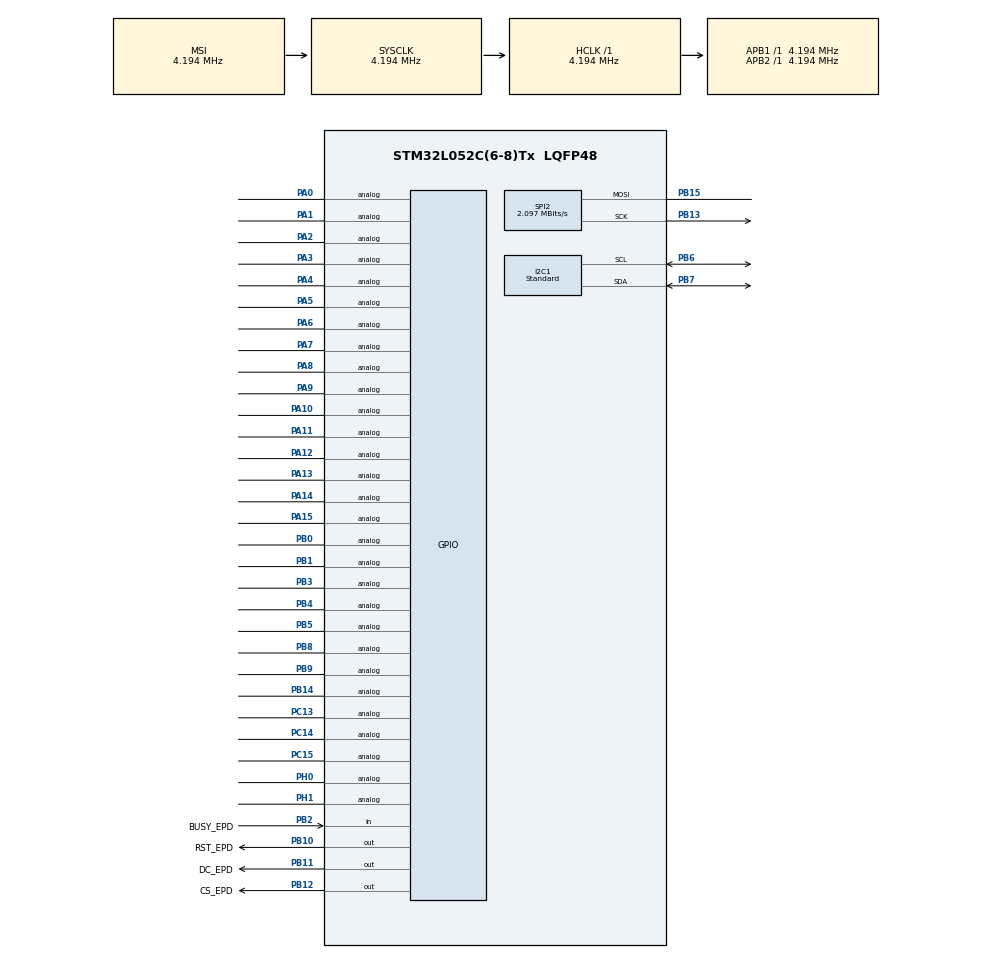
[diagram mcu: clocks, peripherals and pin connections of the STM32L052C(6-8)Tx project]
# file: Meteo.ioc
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ADC.SamplingTime=ADC_SAMPLETIME_160CYCLES_5
I2C1.Analog_Filter=I2C_ANALOGFILTER_DISABLE
I2C1.I2C_Speed_Mode=I2C_Standard
I2C1.Timing=0x00100E16
Mcu.Family=STM32L0
Mcu.Name=STM32L052C(6-8)Tx
Mcu.Package=LQFP48
NVIC.RTC_IRQn=true\:0\:0\:false\:false\:true\:true\:true
PA0.Signal=GPIO_Analog
PA1.Signal=GPIO_Analog
PA10.Signal=GPIO_Analog
PA11.Signal=GPIO_Analog
PA12.Signal=GPIO_Analog
PA13.Signal=GPIO_Analog
PA14.Signal=GPIO_Analog
PA15.Signal=GPIO_Analog
PA2.Signal=GPIO_Analog
PA3.Signal=GPIO_Analog
PA4.Signal=GPIO_Analog
PA5.Signal=GPIO_Analog
PA6.Signal=GPIO_Analog
PA7.Signal=GPIO_Analog
PA8.Signal=GPIO_Analog
PA9.Signal=GPIO_Analog
PB0.Signal=GPIO_Analog
PB1.Signal=GPIO_Analog
PB10.GPIO_Label=RST_EPD
PB10.GPIO_PuPd=GPIO_PULLUP
PB10.GPIO_Speed=GPIO_SPEED_FREQ_LOW
PB10.PinState=GPIO_PIN_SET
PB10.Signal=GPIO_Output
PB11.GPIO_Label=DC_EPD
PB11.GPIO_Speed=GPIO_SPEED_FREQ_LOW
PB11.Signal=GPIO_Output
PB12.GPIO_Label=CS_EPD
PB12.PinState=GPIO_PIN_SET
PB12.Signal=GPIO_Output
PB13.Mode=Simplex_Bidirectional_Master
PB13.Signal=SPI2_SCK
PB14.Signal=GPIO_Analog
PB15.GPIO_Speed=GPIO_SPEED_FREQ_VERY_HIGH
PB15.Mode=Simplex_Bidirectional_Master
PB15.Signal=SPI2_MOSI
PB2.GPIO_Label=BUSY_EPD
PB2.Signal=GPIO_Input
PB3.Signal=GPIO_Analog
PB4.Signal=GPIO_Analog
PB5.Signal=GPIO_Analog
PB6.Mode=I2C
PB6.Signal=I2C1_SCL
PB7.Mode=I2C
PB7.Signal=I2C1_SDA
PB8.Signal=GPIO_Analog
PB9.Signal=GPIO_Analog
PC13.Signal=GPIO_Analog
PC14-OSC32_IN.Signal=GPIO_Analog
PC15-OSC32_OUT.Signal=GPIO_Analog
PH0-OSC_IN.Signal=GPIO_Analog
PH1-OSC_OUT.Signal=GPIO_Analog
ProjectManager.HeapSize=0x200
ProjectManager.StackSize=0x400
ProjectManager.TargetToolchain=MDK-ARM V5
RCC.ADCFreq_Value=16000000
RCC.AHBFreq_Value=4194000
RCC.APB1Freq_Value=4194000
RCC.APB1TimFreq_Value=4194000
RCC.APB2Freq_Value=4194000
RCC.APB2TimFreq_Value=4194000
RCC.HCLKFreq_Value=4194000
RCC.HSE_VALUE=8000000
RCC.HSI16_VALUE=16000000
RCC.HSI48_VALUE=48000000
RCC.HSI_VALUE=16000000
RCC.LSE_VALUE=32768
RCC.MSIClockRange=RCC_MSIRANGE_6
RCC.MSI_VALUE=4194000
RCC.PLLDIV=RCC_PLLDIV_4
RCC.PLLMUL=RCC_PLLMUL_4
RCC.SYSCLKFreq_VALUE=4194000
RCC.Usart2ClockSelection=RCC_USART2CLKSOURCE_SYSCLK
RCC.VCOOutputFreq_Value=64000000
RTC.AsynchPrediv=99
RTC.SynchPrediv=369
RTC.WakeUpClock-WakeUp=RTC_WAKEUPCLOCK_RTCCLK_DIV8
RTC.WakeUpCounter-WakeUp=23124
SPI2.CalculateBaudRate=2.097 MBits/s
SPI2.Direction=SPI_DIRECTION_1LINE
SPI2.Mode=SPI_MODE_MASTER
SPI2.VirtualType=VM_MASTER
SYS.Mode=PWR_PVD_MODE_NORMAL
SYS.PVDLevel=PWR_PVDLEVEL_0
VP_ADC_Vref_Input.Mode=IN-Vrefint
VP_RTC_VS_RTC_Activate.Mode=RTC_Enabled
VP_RTC_VS_RTC_Calendar.Mode=RTC_Calendar
VP_RTC_VS_RTC_WakeUp_intern.Mode=WakeUp
VP_SYS_V_PVD_IN.Mode=Mode_PVD_Int
board=custom

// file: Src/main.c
/* USER CODE BEGIN Header */
/**
  ******************************************************************************
  * @file           : main.c
  * @brief          : Main program body
  ******************************************************************************
  * @attention
  *
  * <h2><center>&copy; Copyright (c) 2021 STMicroelectronics.
  * All rights reserved.</center></h2>
  *
  * This software component is licensed by ST under BSD 3-Clause license,
  * the "License"; You may not use this file except in compliance with the
  * License. You may obtain a copy of the License at:
  *                        opensource.org/licenses/BSD-3-Clause
  *
  ******************************************************************************
  */
/* USER CODE END Header */
#include "main.h"

/* USER CODE BEGIN Includes */
#include "bme280.h"
#include <string.h>
#include <stdint.h>
#include <stdio.h>
#include <stdlib.h>
#include "E-ink_2.13.h"
#include "E-ink_draw.h"

/* USER CODE END Includes */

/* USER CODE BEGIN PTD */
rt_clock RT_C;
float Battery;
/* USER CODE END PTD */

ADC_HandleTypeDef hadc;

I2C_HandleTypeDef hi2c1;

RTC_HandleTypeDef hrtc;

SPI_HandleTypeDef hspi2;

void SystemClock_Config(void);
static void MX_GPIO_Init(void);
static void MX_I2C1_Init(void);
static void MX_SPI2_Init(void);
static void MX_ADC_Init(void);
static void MX_RTC_Init(void);

/* USER CODE BEGIN 0 */
float temperature;
float humidity;
float pressure;
struct bme280_dev dev;
struct bme280_data comp_data;
int8_t rslt;
char Str[12];
uint8_t Old_min=128;
char line1[16];
char line2[16];

//------------------------------------------------------------------------------
// File generated by LCD Assistant
// http://en.radzio.dxp.pl/bitmap_converter/
//------------------------------------------------------------------------------
const unsigned char Batt_Full [] = { // 100% Battery Icon
0x20, 0x00, 0x10, 0x00,
0xFF, 0xFF, 0x03, 0xFB, 0xFB, 0xFB, 0xFB, 0x03, 0xFB, 0xFB, 0xFB, 0xFB, 0x03, 0xFB, 0xFB, 0xFB,
0xFB, 0x03, 0xFB, 0xFB, 0xFB, 0xFB, 0x03, 0xFF, 0xFF, 0xF8, 0xF8, 0x00, 0x00, 0x00, 0x00, 0x00,
0x0F, 0x0F, 0x0C, 0x0D, 0x0D, 0x0D, 0x0D, 0x0C, 0x0D, 0x0D, 0x0D, 0x0D, 0x0C, 0x0D, 0x0D, 0x0D,
0x0D, 0x0C, 0x0D, 0x0D, 0x0D, 0x0D, 0x0C, 0x0F, 0x0F, 0x01, 0x01, 0x00, 0x00, 0x00, 0x00, 0x00
};

const unsigned char Batt_75 [] = { // 75% Battery Icon
0x20, 0x00, 0x10, 0x00,
0xFF, 0xFF, 0x03, 0xFB, 0xFB, 0xFB, 0xFB, 0x03, 0xFB, 0xFB, 0xFB, 0xFB, 0x03, 0xFB, 0xFB, 0xFB,
0xFB, 0x03, 0x03, 0x03, 0x03, 0x03, 0x03, 0xFF, 0xFF, 0xF8, 0xF8, 0x00, 0x00, 0x00, 0x00, 0x00,
0x0F, 0x0F, 0x0C, 0x0D, 0x0D, 0x0D, 0x0D, 0x0C, 0x0D, 0x0D, 0x0D, 0x0D, 0x0C, 0x0D, 0x0D, 0x0D,
0x0D, 0x0C, 0x0C, 0x0C, 0x0C, 0x0C, 0x0C, 0x0F, 0x0F, 0x01, 0x01, 0x00, 0x00, 0x00, 0x00, 0x00};

const unsigned char Batt_50 [] = { // 50% Battery Icon
0x20, 0x00, 0x10, 0x00,
0xFF, 0xFF, 0x03, 0xFB, 0xFB, 0xFB, 0xFB, 0x03, 0xFB, 0xFB, 0xFB, 0xFB, 0x03, 0x03, 0x03, 0x03,
0x03, 0x03, 0x03, 0x03, 0x03, 0x03, 0x03, 0xFF, 0xFF, 0xF8, 0xF8, 0x00, 0x00, 0x00, 0x00, 0x00,
0x0F, 0x0F, 0x0C, 0x0D, 0x0D, 0x0D, 0x0D, 0x0C, 0x0D, 0x0D, 0x0D, 0x0D, 0x0C, 0x0C, 0x0C, 0x0C,
0x0C, 0x0C, 0x0C, 0x0C, 0x0C, 0x0C, 0x0C, 0x0F, 0x0F, 0x01, 0x01, 0x00, 0x00, 0x00, 0x00, 0x00
	};
const unsigned char Batt_25 [] = { // 25% Battery Icon
0x20, 0x00, 0x10, 0x00,
0xFF, 0xFF, 0x03, 0xFB, 0xFB, 0xFB, 0xFB, 0x03, 0x03, 0x03, 0x03, 0x03, 0x03, 0x03, 0x03, 0x03,
0x03, 0x03, 0x03, 0x03, 0x03, 0x03, 0x03, 0xFF, 0xFF, 0xF8, 0xF8, 0x00, 0x00, 0x00, 0x00, 0x00,
0x0F, 0x0F, 0x0C, 0x0D, 0x0D, 0x0D, 0x0D, 0x0C, 0x0C, 0x0C, 0x0C, 0x0C, 0x0C, 0x0C, 0x0C, 0x0C,
0x0C, 0x0C, 0x0C, 0x0C, 0x0C, 0x0C, 0x0C, 0x0F, 0x0F, 0x01, 0x01, 0x00, 0x00, 0x00, 0x00, 0x00
};

const unsigned char Batt_0 [] = { // 0% Battery Icon
0x20, 0x00, 0x10, 0x00,
0xFF, 0xFF, 0x03, 0x03, 0x03, 0x03, 0x03, 0x03, 0x03, 0x03, 0x03, 0x03, 0x03, 0x03, 0x03, 0x03,
0x03, 0x03, 0x03, 0x03, 0x03, 0x03, 0x03, 0xFF, 0xFF, 0xF8, 0xF8, 0x00, 0x00, 0x00, 0x00, 0x00,
0x0F, 0x0F, 0x0C, 0x0C, 0x0C, 0x0C, 0x0C, 0x0C, 0x0C, 0x0C, 0x0C, 0x0C, 0x0C, 0x0C, 0x0C, 0x0C,
0x0C, 0x0C, 0x0C, 0x0C, 0x0C, 0x0C, 0x0C, 0x0F, 0x0F, 0x01, 0x01, 0x00, 0x00, 0x00, 0x00, 0x00};

const unsigned char MainScr [] = { // Main Icon
0xFA, 0x00, 0x80, 0x00,
0x00, 0x00, 0x00, 0x00, 0x00, 0x00, 0x00, 0x00, 0x00, 0x00, 0x00, 0x00, 0x00, 0x00, 0x00, 0x00,
0x00, 0x00, 0x00, 0x00, 0x00, 0x00, 0x00, 0x00, 0x00, 0x00, 0x00, 0x80, 0xE0, 0x60, 0x60, 0x60,
0x60, 0x60, 0x60, 0x60, 0x60, 0xE0, 0xC0, 0x00, 0x00, 0x00, 0x00, 0x00, 0x00, 0x00, 0x00, 0x00,
0x00, 0x00, 0x00, 0x00, 0x00, 0x00, 0x00, 0x00, 0x00, 0x00, 0x00, 0x00, 0x00, 0x00, 0x00, 0x00,
0x00, 0x00, 0x00, 0x00, 0x00, 0x00, 0x00, 0x00, 0x00, 0x00, 0x00, 0x00, 0x00, 0x00, 0x00, 0x00,
0x00, 0x00, 0x00, 0x00, 0x00, 0x00, 0x00, 0x00, 0x00, 0x00, 0x00, 0x00, 0x00, 0x00, 0x00, 0x00,
0x00, 0x00, 0x00, 0x00, 0x00, 0x00, 0x00, 0x00, 0x00, 0x00, 0x00, 0x00, 0x00, 0x00, 0x00, 0x00,
0x00, 0x00, 0x00, 0x00, 0x00, 0x00, 0x00, 0x00, 0x00, 0x00, 0x00, 0x00, 0x00, 0x00, 0x00, 0x00,
0x00, 0x00, 0x00, 0x00, 0x00, 0x00, 0x00, 0x00, 0x00, 0x00, 0x00, 0x00, 0x00, 0x00, 0x00, 0x00,
0x00, 0x00, 0x00, 0x00, 0x00, 0x00, 0x00, 0x00, 0x00, 0x00, 0x00, 0x00, 0x00, 0x00, 0x00, 0x00,
0x00, 0x00, 0x00, 0x00, 0x00, 0x00, 0x00, 0x00, 0x00, 0x80, 0xC0, 0xE0, 0x70, 0x30, 0x30, 0x70,
0xE0, 0xC0, 0x80, 0x00, 0x00, 0x00, 0x00, 0x00, 0x00, 0x00, 0x00, 0x00, 0x80, 0xC0, 0xE0, 0xE0,
0xE0, 0xF0, 0xF0, 0xF0, 0xF0, 0xF0, 0xF0, 0xE0, 0xE0, 0xC0, 0x80, 0x00, 0x00, 0x00, 0x00, 0x00,
0x00, 0x00, 0x00, 0x00, 0x00, 0x00, 0x00, 0x00, 0x00, 0x00, 0x00, 0x00, 0x00, 0x00, 0x00, 0x00,
0x00, 0x00, 0x00, 0x00, 0x00, 0x00, 0x00, 0x00, 0x00, 0x00, 0x00, 0x00, 0x00, 0x00, 0x00, 0x00,
0x00, 0x00, 0x00, 0x00, 0x00, 0x00, 0x00, 0x00, 0x00, 0x00, 0x00, 0x00, 0x00, 0x00, 0x00, 0x00,
0x00, 0x00, 0x00, 0x00, 0x00, 0x00, 0x00, 0x00, 0x00, 0x00, 0x00, 0x00, 0x00, 0x00, 0x00, 0x00,
0x00, 0x00, 0x00, 0x00, 0x00, 0xFF, 0xFF, 0x00, 0x00, 0xFE, 0xFE, 0xFE, 0xFE, 0x00, 0x00, 0xFF,
0xFF, 0x00, 0x00, 0x00, 0x00, 0x9C, 0x9C, 0x9C, 0x9C, 0x9C, 0x9C, 0x1C, 0x1C, 0x1C, 0x00, 0x00,
0x00, 0x00, 0x00, 0x00, 0x00, 0x00, 0x00, 0x00, 0x00, 0x00, 0x00, 0x00, 0x00, 0x00, 0x00, 0x00,
0x00, 0x00, 0x00, 0x00, 0x00, 0x00, 0x00, 0x00, 0x00, 0x00, 0x00, 0x00, 0x00, 0x00, 0x00, 0x00,
0x00, 0x00, 0x00, 0x00, 0x00, 0x00, 0x00, 0x00, 0x00, 0x00, 0x00, 0x00, 0x00, 0x00, 0x00, 0x00,
0x00, 0x00, 0x00, 0x00, 0x00, 0x00, 0x00, 0x00, 0x00, 0x00, 0x00, 0x00, 0x00, 0x00, 0x00, 0x00,
0x00, 0x00, 0x00, 0x00, 0x00, 0x00, 0x00, 0x00, 0x00, 0x00, 0x00, 0x00, 0x00, 0x00, 0x00, 0x00,
0x00, 0x00, 0x00, 0x00, 0x00, 0x00, 0x00, 0x00, 0x00, 0x00, 0x00, 0x00, 0x00, 0x00, 0x00, 0x00,
0x00, 0x00, 0x00, 0x00, 0x00, 0x00, 0x00, 0x00, 0x00, 0x00, 0x00, 0x00, 0x00, 0x00, 0x00, 0x00,
0x00, 0x00, 0x00, 0x1F, 0x3F, 0x70, 0xE0, 0xC0, 0xC0, 0xE0, 0x70, 0x3F, 0x1F, 0x00, 0x00, 0x00,
0x00, 0x00, 0x80, 0xF8, 0xFE, 0x7F, 0x0F, 0x07, 0x03, 0x01, 0x01, 0x00, 0x00, 0x00, 0x00, 0x00,
0x00, 0x01, 0x03, 0x07, 0x1F, 0x3F, 0x3E, 0x10, 0x00, 0x00, 0x00, 0x00, 0x00, 0x00, 0x00, 0x00,
0x00, 0x00, 0x00, 0x00, 0x00, 0x00, 0x00, 0x00, 0x00, 0x00, 0x00, 0x00, 0x00, 0x00, 0x00, 0x00,
0x00, 0x00, 0x00, 0x00, 0x00, 0x00, 0x00, 0x00, 0x00, 0x00, 0x00, 0x00, 0x00, 0x00, 0x00, 0x00,
0x00, 0x00, 0x00, 0x00, 0x00, 0x00, 0x00, 0x00, 0x00, 0x00, 0x00, 0x00, 0x00, 0x00, 0x00, 0x00,
0x00, 0x00, 0x00, 0x00, 0x00, 0x00, 0x00, 0x00, 0x00, 0x00, 0x00, 0x00, 0x00, 0x80, 0xC0, 0xFF,
0x7F, 0x00, 0x00, 0xFF, 0xFF, 0xFF, 0xFF, 0x00, 0x00, 0x7F, 0xFF, 0xC0, 0x80, 0x00, 0x00, 0x73,
0x73, 0x73, 0x73, 0x73, 0x73, 0x70, 0x70, 0x70, 0x00, 0x00, 0x00, 0x00, 0x00, 0x00, 0x00, 0x00,
0x00, 0x00, 0x00, 0x00, 0x00, 0x00, 0x00, 0x00, 0x00, 0x00, 0x00, 0x00, 0x00, 0x00, 0x00, 0x00,
0x00, 0x00, 0x00, 0x00, 0x00, 0x00, 0x00, 0x00, 0x00, 0x00, 0x00, 0x00, 0x00, 0x00, 0x00, 0x00,
0x00, 0x00, 0x00, 0x00, 0x00, 0x00, 0x00, 0x00, 0x00, 0x00, 0x00, 0x00, 0x00, 0x00, 0x00, 0x00,
0x00, 0x00, 0x00, 0x00, 0x00, 0x00, 0x00, 0x00, 0x00, 0x00, 0x00, 0x00, 0x00, 0x00, 0x00, 0x00,
0x00, 0x00, 0x00, 0x00, 0x00, 0x00, 0x00, 0x00, 0x00, 0x00, 0x00, 0x00, 0x00, 0x00, 0x00, 0x00,
0x00, 0x00, 0x00, 0x00, 0x00, 0x00, 0x00, 0x00, 0x00, 0x00, 0x00, 0x00, 0x00, 0x00, 0x00, 0x00,
0x00, 0x00, 0x00, 0x00, 0x00, 0x00, 0x00, 0x00, 0x00, 0x00, 0x00, 0x00, 0x00, 0x00, 0x00, 0x00,
0x00, 0x00, 0x00, 0x00, 0x00, 0x00, 0x00, 0x00, 0x00, 0x00, 0x00, 0x00, 0xFF, 0xFF, 0xFF, 0x00,
0x00, 0x00, 0x00, 0x00, 0x00, 0x00, 0x00, 0x00, 0x00, 0x00, 0x00, 0x00, 0x00, 0x00, 0x00, 0x00,
0x00, 0x00, 0x00, 0x00, 0x00, 0x00, 0x00, 0x00, 0x00, 0x00, 0x00, 0x00, 0x00, 0x00, 0x00, 0x00,
0x00, 0x00, 0x00, 0x00, 0x00, 0x00, 0x00, 0x00, 0x00, 0x00, 0x00, 0x00, 0x00, 0x00, 0x00, 0x00,
0x00, 0x00, 0x00, 0x00, 0x00, 0x00, 0x00, 0x00, 0x00, 0x00, 0x00, 0x00, 0x00, 0x00, 0x00, 0x00,
0x00, 0x00, 0x00, 0x00, 0x00, 0x00, 0x00, 0x00, 0x00, 0x00, 0x00, 0x00, 0x00, 0x00, 0x00, 0x00,
0x00, 0x00, 0x00, 0x00, 0x00, 0x3E, 0x7E, 0xFF, 0xC3, 0x00, 0x1C, 0x3E, 0x7F, 0xFF, 0xFF, 0xFF,
0xFF, 0x7F, 0x3E, 0x1C, 0x80, 0xC3, 0xFF, 0x7F, 0x3E, 0x00, 0xC0, 0xCE, 0xCE, 0xCE, 0xCE, 0xC0,
0xC0, 0xC0, 0x00, 0x00, 0x00, 0x00, 0x00, 0x00, 0x00, 0x00, 0x00, 0x00, 0x00, 0x00, 0x00, 0x00,
0x00, 0x00, 0x00, 0x00, 0x00, 0x00, 0x00, 0x00, 0x00, 0x00, 0x00, 0x00, 0x00, 0x00, 0x00, 0x00,
0x00, 0x00, 0x00, 0x00, 0x00, 0x00, 0x00, 0x00, 0x00, 0x00, 0x00, 0x00, 0x00, 0x00, 0x00, 0x00,
0x00, 0x00, 0x00, 0x00, 0x00, 0x00, 0x00, 0x00, 0x00, 0x00, 0x00, 0x00, 0x00, 0x00, 0x00, 0x00,
0x00, 0x00, 0x00, 0x00, 0x00, 0x00, 0x00, 0x00, 0x00, 0x00, 0x00, 0x00, 0x00, 0x00, 0x00, 0x00,
0x00, 0x00, 0x00, 0x00, 0x00, 0x00, 0x00, 0x00, 0x00, 0x00, 0x00, 0x00, 0x00, 0x00, 0x00, 0x00,
0x00, 0x00, 0x00, 0x00, 0x00, 0x00, 0x00, 0x00, 0x00, 0x00, 0x00, 0x00, 0x00, 0x00, 0x00, 0x00,
0x00, 0x00, 0x00, 0x00, 0x00, 0x00, 0x00, 0x00, 0x00, 0x00, 0x00, 0x00, 0x00, 0x00, 0x00, 0x00,
0x00, 0x00, 0x00, 0x00, 0x00, 0x00, 0x01, 0x0F, 0x7F, 0xFE, 0xF8, 0xE0, 0xC0, 0x80, 0x80, 0x00,
0x00, 0x00, 0x00, 0x00, 0x00, 0x80, 0x80, 0xC0, 0xF0, 0xFC, 0xFE, 0x3E, 0x06, 0x00, 0x00, 0x00,
0x00, 0x00, 0x00, 0x00, 0x00, 0x00, 0x00, 0x00, 0x00, 0x00, 0x00, 0x00, 0x00, 0x00, 0x00, 0x00,
0x00, 0x00, 0x00, 0x00, 0x00, 0x00, 0x00, 0x00, 0x00, 0x00, 0x00, 0x00, 0x00, 0x00, 0x00, 0x00,
0x00, 0x00, 0x00, 0x00, 0x00, 0x00, 0x00, 0x00, 0x00, 0x00, 0x00, 0x00, 0x00, 0x00, 0x00, 0x00,
0x00, 0x00, 0x00, 0x00, 0x00, 0x00, 0x00, 0x00, 0x00, 0x00, 0x00, 0x00, 0x00, 0x00, 0x00, 0x00,
0x00, 0x00, 0x01, 0x03, 0x03, 0x06, 0x0C, 0x0C, 0x0C, 0x0C, 0x0C, 0x0C, 0x06, 0x02, 0x03, 0x01,
0x00, 0x00, 0x00, 0x00, 0x01, 0x01, 0x01, 0x01, 0x01, 0x01, 0x01, 0x01, 0x00, 0x00, 0x00, 0x00,
0x00, 0x00, 0x00, 0x00, 0x00, 0x00, 0x00, 0x00, 0x00, 0x00, 0x00, 0x00, 0x00, 0x00, 0x00, 0x00,
0x00, 0x00, 0x00, 0x00, 0x00, 0x00, 0x00, 0x00, 0x00, 0x00, 0x00, 0x00, 0x00, 0x00, 0x00, 0x00,
0x00, 0x00, 0x00, 0x00, 0x00, 0x00, 0x00, 0x00, 0x00, 0x00, 0x00, 0x00, 0x00, 0x00, 0x00, 0x00,
0x00, 0x00, 0x00, 0x00, 0x00, 0x00, 0x00, 0x00, 0x00, 0x00, 0x00, 0x00, 0x00, 0x00, 0x00, 0x00,
0x00, 0x00, 0x00, 0x00, 0x00, 0x00, 0x00, 0x00, 0x00, 0x00, 0x00, 0x00, 0x00, 0x00, 0x00, 0x00,
0x00, 0x00, 0x00, 0x00, 0x00, 0x00, 0x00, 0x00, 0x00, 0x00, 0x00, 0x00, 0x00, 0x00, 0x00, 0x00,
0x00, 0x00, 0x00, 0x00, 0x00, 0x00, 0x00, 0x00, 0x00, 0x00, 0x00, 0x00, 0x00, 0x00, 0x00, 0x00,
0x00, 0x00, 0x00, 0x00, 0x00, 0x00, 0x00, 0x00, 0x00, 0x00, 0x00, 0x00, 0x00, 0x00, 0x00, 0x00,
0x00, 0x00, 0x00, 0x00, 0x01, 0x03, 0x07, 0x07, 0x0F, 0x0F, 0x0F, 0x0F, 0x0F, 0x0F, 0x0F, 0x07,
0x07, 0x07, 0x03, 0x01, 0x00, 0x00, 0x00, 0x00, 0x00, 0x00, 0x00, 0x00, 0x00, 0x00, 0x00, 0x00,
0x00, 0x00, 0x00, 0x00, 0x00, 0x00, 0x00, 0x00, 0x00, 0x00, 0x00, 0x00, 0x00, 0x00, 0x00, 0x00,
0x00, 0x00, 0x00, 0x00, 0x00, 0x00, 0x00, 0x00, 0x00, 0x00, 0x00, 0x00, 0x00, 0x00, 0x00, 0x00,
0x00, 0x00, 0x00, 0x00, 0x00, 0x00, 0x00, 0x00, 0x00, 0x00, 0x00, 0x00, 0x00, 0x00, 0x00, 0x00,
0x00, 0x00, 0x00, 0x00, 0x00, 0x00, 0x80, 0x80, 0x00, 0x00, 0x00, 0x00, 0x00, 0x00, 0x00, 0x00,
0x00, 0x00, 0x00, 0x00, 0x80, 0x80, 0x00, 0x00, 0x00, 0x00, 0x00, 0x00, 0x00, 0x80, 0x80, 0x80,
0x80, 0x80, 0x80, 0x80, 0x80, 0x80, 0x00, 0x00, 0x00, 0x00, 0x00, 0x00, 0x00, 0x00, 0x00, 0x00,
0x00, 0x00, 0x00, 0x00, 0x00, 0x00, 0x00, 0x00, 0x00, 0x00, 0x00, 0x00, 0x00, 0x00, 0x00, 0x00,
0x00, 0x00, 0x00, 0x00, 0x00, 0x00, 0x00, 0x00, 0x00, 0x00, 0x00, 0x00, 0x00, 0x00, 0x00, 0x00,
0x00, 0x00, 0x00, 0x00, 0x00, 0x00, 0x00, 0x00, 0x00, 0x00, 0x00, 0x00, 0x00, 0x00, 0x00, 0x00,
0x00, 0x00, 0x00, 0x00, 0x00, 0x00, 0x00, 0x00, 0x00, 0x00, 0x00, 0x00, 0x00, 0x00, 0x00, 0x00,
0x00, 0x00, 0x00, 0x00, 0x00, 0x00, 0x00, 0x00, 0x00, 0x00, 0x00, 0x00, 0x00, 0x00, 0x00, 0x00,
0x00, 0x00, 0x00, 0x00, 0x00, 0x00, 0x00, 0x00, 0x00, 0x00, 0x00, 0x00, 0x00, 0x00, 0x00, 0x00,
0x00, 0x00, 0x00, 0x00, 0x00, 0x00, 0x00, 0x00, 0x00, 0x00, 0x00, 0x00, 0x00, 0x00, 0x00, 0x00,
0x00, 0x00, 0x00, 0x00, 0x00, 0x00, 0x00, 0x00, 0x00, 0x00, 0x00, 0x00, 0x40, 0xC0, 0xC0, 0xC0,
0xC0, 0xC0, 0xC0, 0xC0, 0xC0, 0xC0, 0xC0, 0xC0, 0xC0, 0xC0, 0xC0, 0xC0, 0xC0, 0xC0, 0xC0, 0xC0,
0x40, 0x40, 0x00, 0x00, 0x00, 0x00, 0x00, 0x00, 0x00, 0x00, 0x00, 0x00, 0x00, 0x00, 0x00, 0x00,
0x00, 0x00, 0x00, 0x00, 0x00, 0x00, 0x00, 0x00, 0x00, 0x00, 0x00, 0x00, 0x00, 0x00, 0x00, 0x00,
0x00, 0x00, 0x00, 0x00, 0x00, 0x00, 0x00, 0x00, 0x00, 0x00, 0x00, 0x00, 0x00, 0x00, 0x00, 0x00,
0x00, 0x00, 0x00, 0x00, 0x00, 0x00, 0x00, 0x00, 0x00, 0x00, 0x00, 0x00, 0x00, 0x00, 0x00, 0x03,
0x0F, 0xFF, 0xFF, 0xFE, 0xF8, 0x00, 0x00, 0x00, 0x00, 0x00, 0x00, 0x00, 0x00, 0x03, 0x0F, 0xFF,
0xFF, 0xFE, 0xF8, 0x00, 0x00, 0x00, 0x00, 0x03, 0x03, 0x03, 0xE3, 0xE3, 0xE3, 0xE3, 0xFF, 0xFF,
0xFF, 0x00, 0x00, 0x00, 0x00, 0x00, 0x00, 0x00, 0x00, 0x00, 0x00, 0x00, 0x00, 0x00, 0x00, 0x00,
0x00, 0x00, 0x00, 0x00, 0x00, 0x00, 0x00, 0x00, 0x00, 0x00, 0x00, 0x00, 0x00, 0x00, 0x00, 0x00,
0x00, 0x00, 0x00, 0x00, 0x00, 0x00, 0x00, 0x00, 0x00, 0x00, 0x00, 0x00, 0x00, 0x00, 0x00, 0x00,
0x00, 0x00, 0x00, 0x00, 0x00, 0x00, 0x00, 0x00, 0x00, 0x00, 0x00, 0x00, 0x00, 0x00, 0x00, 0x00,
0x00, 0x00, 0x00, 0x00, 0x00, 0x00, 0x00, 0x00, 0x00, 0x00, 0x00, 0x00, 0x00, 0x00, 0x00, 0x00,
0x00, 0x00, 0x00, 0x00, 0x00, 0x00, 0x00, 0x00, 0x00, 0x00, 0x00, 0x00, 0x00, 0x00, 0x00, 0x00,
0x00, 0x00, 0x00, 0x00, 0x00, 0x00, 0x00, 0x00, 0x00, 0x00, 0x00, 0x00, 0x00, 0x00, 0x00, 0x00,
0x00, 0x00, 0x00, 0x00, 0x00, 0x40, 0xC0, 0xC0, 0xC0, 0xC0, 0xC0, 0xC0, 0xC0, 0xC0, 0xC0, 0xC0,
0xC0, 0xC0, 0xC0, 0x00, 0x00, 0x00, 0x00, 0x00, 0xFF, 0xFF, 0xFF, 0x00, 0x00, 0x00, 0x00, 0x00,
0x00, 0x00, 0x00, 0x00, 0x00, 0x00, 0xFF, 0xFF, 0xFF, 0x01, 0x00, 0x00, 0x00, 0x00, 0x00, 0x00,
0x00, 0x80, 0x80, 0x80, 0xC0, 0xC0, 0xC0, 0xC0, 0xC0, 0xC0, 0x80, 0x00, 0x00, 0x00, 0x00, 0x00,
0x00, 0x00, 0x00, 0x00, 0x00, 0x00, 0x00, 0x00, 0x00, 0x00, 0x00, 0x00, 0x00, 0x00, 0x00, 0x00,
0x00, 0x00, 0x00, 0x00, 0x00, 0x00, 0x00, 0x00, 0x00, 0x00, 0x00, 0x00, 0x00, 0x00, 0x00, 0x00,
0x00, 0x00, 0x00, 0x00, 0x00, 0x00, 0x00, 0xF0, 0xF8, 0xFC, 0xFE, 0x0F, 0x07, 0x03, 0x01, 0x00,
0x00, 0x00, 0x00, 0x00, 0x00, 0xF0, 0xFC, 0xFE, 0xFF, 0x1F, 0x07, 0x01, 0x00, 0x00, 0x00, 0x00,
0x00, 0x00, 0x00, 0x00, 0x38, 0x38, 0x38, 0x38, 0xFF, 0xFF, 0xFF, 0x00, 0x00, 0x00, 0x00, 0x00,
0x00, 0x00, 0x00, 0x00, 0x00, 0x00, 0x00, 0x00, 0x00, 0x00, 0x00, 0x00, 0x00, 0x00, 0x00, 0x00,
0x00, 0x00, 0x00, 0x00, 0x00, 0x00, 0x00, 0x00, 0x00, 0x00, 0x00, 0x00, 0x00, 0x00, 0x00, 0x00,
0x00, 0x00, 0x00, 0x00, 0x00, 0x00, 0x00, 0x00, 0x00, 0x00, 0x00, 0x00, 0x00, 0x00, 0x00, 0x00,
0x00, 0x00, 0x00, 0x00, 0x00, 0x00, 0x00, 0x00, 0x00, 0x00, 0x00, 0x00, 0x00, 0x00, 0x00, 0x00,
0x00, 0x00, 0x00, 0x00, 0x00, 0x00, 0x00, 0x00, 0x00, 0x00, 0x00, 0x00, 0x00, 0x00, 0x00, 0x00,
0x00, 0x00, 0x00, 0x00, 0x00, 0x00, 0x00, 0x00, 0x00, 0x00, 0x00, 0x00, 0x00, 0x00, 0x00, 0x00,
0x00, 0x00, 0x00, 0x00, 0x00, 0x00, 0x00, 0x00, 0x00, 0x00, 0x00, 0x00, 0x00, 0x00, 0x00, 0x00,
0x00, 0xFF, 0xFF, 0xFF, 0x00, 0x00, 0x00, 0x00, 0x00, 0x01, 0x03, 0x0F, 0x0F, 0x00, 0x00, 0x00,
0x00, 0x00, 0xFF, 0xFF, 0xFF, 0x00, 0x00, 0x00, 0x00, 0x00, 0x00, 0x00, 0x00, 0x00, 0x00, 0x00,
0xFF, 0xFF, 0xFF, 0x00, 0x00, 0x00, 0x00, 0x00, 0x00, 0x0F, 0x0F, 0x03, 0x01, 0x00, 0x00, 0x00,
0x00, 0x01, 0x03, 0xFF, 0xFF, 0xFF, 0x00, 0x00, 0x00, 0x00, 0x00, 0x00, 0x00, 0x00, 0x00, 0x00,
0x00, 0x00, 0x00, 0x00, 0x00, 0x00, 0x00, 0x00, 0x00, 0x00, 0x00, 0x00, 0x00, 0x00, 0x00, 0x00,
0x00, 0x00, 0x00, 0x00, 0x00, 0x00, 0x00, 0x00, 0x00, 0x00, 0x00, 0x00, 0x00, 0x00, 0x00, 0x00,
0x00, 0x03, 0x07, 0xFF, 0xFF, 0xF8, 0xF0, 0x00, 0x00, 0x00, 0x00, 0x00, 0x00, 0x00, 0x00, 0x03,
0x07, 0xFF, 0xFF, 0xF8, 0xF0, 0x00, 0x00, 0x00, 0x00, 0x00, 0x00, 0x00, 0x00, 0x00, 0xCE, 0xCE,
0xCE, 0xCE, 0xFF, 0xFF, 0xFF, 0x00, 0x00, 0x00, 0x00, 0x00, 0x00, 0x00, 0x00, 0x00, 0x00, 0x00,
0x00, 0x00, 0x00, 0x00, 0x00, 0x00, 0x00, 0x00, 0x00, 0x00, 0x00, 0x00, 0x00, 0x00, 0x00, 0x00,
0x00, 0x00, 0x00, 0x00, 0x00, 0x00, 0x00, 0x00, 0x00, 0x00, 0x00, 0x00, 0x00, 0x00, 0x00, 0x00,
0x00, 0x00, 0x00, 0x00, 0x00, 0x00, 0x00, 0x00, 0x00, 0x00, 0x00, 0x00, 0x00, 0x00, 0x00, 0x00,
0x00, 0x00, 0x00, 0x00, 0x00, 0x00, 0x00, 0x00, 0x00, 0x00, 0x00, 0x00, 0x00, 0x00, 0x00, 0x00,
0x00, 0x00, 0x00, 0x00, 0x00, 0x00, 0x00, 0x00, 0x00, 0x00, 0x00, 0x00, 0x00, 0x00, 0x00, 0x00,
0x00, 0x00, 0x00, 0x00, 0x00, 0x00, 0x00, 0x00, 0x00, 0x00, 0x00, 0x00, 0x00, 0x00, 0x00, 0x00,
0x00, 0x00, 0x00, 0x00, 0x00, 0x00, 0x00, 0x00, 0x00, 0x00, 0x00, 0xFF, 0xFF, 0xFF, 0x00, 0x00,
0x00, 0x00, 0x00, 0x00, 0x00, 0x00, 0x00, 0x00, 0x00, 0x00, 0x00, 0x00, 0xFF, 0xFF, 0xFF, 0x00,
0x00, 0x00, 0x00, 0x00, 0x00, 0x00, 0x00, 0x00, 0x00, 0x00, 0xFF, 0xFF, 0xFF, 0x00, 0x00, 0x00,
0x00, 0x00, 0xF0, 0xF8, 0xFC, 0x1C, 0x0E, 0x06, 0x02, 0x03, 0x03, 0x03, 0x83, 0xFF, 0xFF, 0xFF,
0x00, 0x00, 0x00, 0x00, 0x00, 0x00, 0x00, 0x00, 0x00, 0x00, 0x00, 0x00, 0x00, 0x00, 0x00, 0x00,
0x00, 0x00, 0x00, 0x00, 0x00, 0x00, 0x00, 0x00, 0x00, 0x00, 0x00, 0x00, 0x00, 0x00, 0x00, 0x00,
0x00, 0x00, 0x00, 0x00, 0x00, 0x00, 0x00, 0x00, 0x00, 0x00, 0x01, 0x03, 0x07, 0x0F, 0x1F, 0x1F,
0x0F, 0x07, 0x03, 0x01, 0x00, 0x00, 0x00, 0x00, 0x01, 0x03, 0x07, 0x0F, 0x1F, 0x1F, 0x0F, 0x07,
0x03, 0x01, 0x00, 0x00, 0x00, 0x00, 0x70, 0x70, 0x71, 0x71, 0x71, 0x71, 0x7F, 0x7F, 0x3F, 0x00,
0x00, 0x00, 0x00, 0x00, 0x00, 0x00, 0x00, 0x00, 0x00, 0x00, 0x00, 0x00, 0x00, 0x00, 0x00, 0x00,
0x00, 0x00, 0x00, 0x00, 0x00, 0x00, 0x00, 0x00, 0x00, 0x00, 0x00, 0x00, 0x00, 0x00, 0x00, 0x00,
0x00, 0x00, 0x00, 0x00, 0x00, 0x00, 0x00, 0x00, 0x00, 0x00, 0x00, 0x00, 0x00, 0x00, 0x00, 0x00,
0x00, 0x00, 0x00, 0x00, 0x00, 0x00, 0x00, 0x00, 0x00, 0x00, 0x00, 0x00, 0x00, 0x00, 0x00, 0x00,
0x00, 0x00, 0x00, 0x00, 0x00, 0x00, 0x00, 0x00, 0x00, 0x00, 0x00, 0x00, 0x00, 0x00, 0x00, 0x00,
0x00, 0x00, 0x00, 0x00, 0x00, 0x00, 0x00, 0x00, 0x00, 0x00, 0x00, 0x00, 0x00, 0x00, 0x00, 0x00,
0x00, 0x00, 0x00, 0x00, 0x00, 0x00, 0x00, 0x00, 0x00, 0x00, 0x00, 0x00, 0x00, 0x00, 0x00, 0x00,
0x00, 0x00, 0x00, 0x08, 0x0C, 0x0F, 0x0F, 0x0F, 0x0E, 0x08, 0x08, 0x00, 0x00, 0x00, 0x00, 0x00,
0x00, 0x00, 0x00, 0x00, 0x08, 0x0C, 0x0F, 0x0F, 0x0F, 0x0E, 0x08, 0x08, 0x00, 0x00, 0x00, 0x00,
0x00, 0x00, 0x08, 0x0C, 0x0F, 0x0F, 0x0F, 0x0E, 0x08, 0x08, 0x00, 0x00, 0x01, 0x07, 0x07, 0x0F,
0x0E, 0x0C, 0x0C, 0x04, 0x06, 0x02, 0x01, 0x0F, 0x0F, 0x0F, 0x0E, 0x08, 0x08, 0x00, 0x00, 0x00,
0x00, 0x00, 0x00, 0x00, 0x00, 0x00, 0x00, 0x00, 0x00, 0x00, 0x00, 0x00, 0x00, 0x00, 0x00, 0x00,
0x00, 0x00, 0x00, 0x00, 0x00, 0x00, 0x00, 0x00, 0x00, 0x00, 0x00, 0x00, 0x00, 0x00, 0x00, 0x00,
0x00, 0x00, 0x00, 0x00, 0x00, 0x00, 0x00, 0x00, 0x00, 0x00, 0x00, 0x00, 0x00, 0x00, 0x00, 0x80,
0x80, 0x80, 0x80, 0x80, 0x80, 0x80, 0x80, 0x80, 0x80, 0x80, 0x80, 0x00, 0x00, 0x00, 0x00, 0x00,
0x00, 0x00, 0x00, 0x00, 0x00, 0x00, 0x00, 0x00, 0x00, 0x00, 0x00, 0x00, 0x00, 0x00, 0x00, 0x00,
0x00, 0x00, 0x00, 0x00, 0x00, 0x00, 0x00, 0x00, 0x00, 0x00, 0x00, 0x00, 0x00, 0x00, 0x00, 0x00,
0x00, 0x00, 0x00, 0x00, 0x00, 0x00, 0x00, 0x00, 0x00, 0x00, 0x00, 0x00, 0x00, 0x00, 0x00, 0x00,
0x00, 0x00, 0x00, 0x00, 0x00, 0x00, 0x00, 0x00, 0x00, 0x00, 0x00, 0x00, 0x00, 0x00, 0x00, 0x00,
0x00, 0x00, 0x00, 0x00, 0x00, 0x00, 0x00, 0x00, 0x00, 0x00, 0x00, 0x00, 0x00, 0x00, 0x00, 0x00,
0x00, 0x00, 0x00, 0x00, 0x00, 0x00, 0x00, 0x00, 0x00, 0x00, 0x00, 0x00, 0x00, 0x00, 0x00, 0x00,
0x00, 0x00, 0x00, 0x00, 0x00, 0x00, 0x00, 0x00, 0x00, 0x00, 0x00, 0x00, 0x00, 0x00, 0x00, 0x00,
0x00, 0x00, 0x00, 0x00, 0x00, 0x00, 0x00, 0x00, 0x00, 0x00, 0x00, 0x00, 0x00, 0x00, 0x00, 0x00,
0x00, 0x00, 0x00, 0x00, 0x00, 0x00, 0x00, 0x00, 0x00, 0x00, 0x00, 0x00, 0x00, 0x00, 0x00, 0x00,
0x00, 0x00, 0x00, 0x00, 0x00, 0x00, 0x00, 0x00, 0x00, 0x00, 0x00, 0x00, 0x00, 0x00, 0x00, 0x00,
0x00, 0x00, 0x00, 0x00, 0x00, 0x00, 0x00, 0x00, 0x00, 0x00, 0x00, 0x00, 0x00, 0x00, 0x00, 0x00,
0x00, 0x00, 0x00, 0x00, 0x00, 0x00, 0x00, 0x00, 0x00, 0x00, 0x00, 0x00, 0x00, 0x00, 0x00, 0x00,
0x00, 0x00, 0x00, 0x00, 0x00, 0x00, 0x00, 0x00, 0x00, 0x00, 0x00, 0x00, 0x00, 0x00, 0x00, 0x00,
0x00, 0x00, 0x00, 0x00, 0x00, 0x00, 0x00, 0x00, 0x00, 0x00, 0x00, 0x00, 0x00, 0x00, 0x00, 0x80,
0xC0, 0xE0, 0xF0, 0x38, 0x3C, 0x1C, 0x0E, 0x86, 0xC7, 0xC3, 0x63, 0x63, 0x33, 0x33, 0x33, 0x33,
0x33, 0x33, 0x63, 0xE3, 0xC7, 0x87, 0x0E, 0x0E, 0x1C, 0x3C, 0x78, 0xF0, 0xE0, 0xC0, 0x80, 0x00,
0x00, 0x00, 0x00, 0x00, 0x00, 0x00, 0x00, 0x00, 0x00, 0x00, 0x00, 0x00, 0x00, 0x00, 0x00, 0x00,
0x00, 0x00, 0x00, 0x00, 0x00, 0x00, 0x00, 0x00, 0x00, 0x00, 0x00, 0x00, 0x00, 0x00, 0x00, 0x00,
0x00, 0x00, 0x00, 0x00, 0x00, 0x00, 0x00, 0x00, 0x00, 0x00, 0x00, 0x00, 0x00, 0x00, 0x00, 0x00,
0x00, 0x00, 0x00, 0x00, 0x00, 0x00, 0x00, 0x00, 0x00, 0x00, 0x00, 0x00, 0x00, 0x00, 0x00, 0x00,
0x00, 0x00, 0x00, 0x00, 0x00, 0x00, 0x00, 0x00, 0x00, 0x00, 0x00, 0x00, 0x00, 0x00, 0x00, 0x00,
0x00, 0x00, 0x00, 0x00, 0x00, 0x00, 0x00, 0x00, 0x00, 0x00, 0x00, 0x00, 0x00, 0x00, 0x00, 0x00,
0x00, 0x00, 0x00, 0x00, 0x00, 0x00, 0x00, 0x00, 0x00, 0x00, 0x00, 0x00, 0x00, 0x00, 0x00, 0x00,
0x00, 0x00, 0x00, 0x00, 0x00, 0x00, 0x00, 0x00, 0xC0, 0xF0, 0xF8, 0xFC, 0x3C, 0x1E, 0x0E, 0x0E,
0x0E, 0x0E, 0x0E, 0x1E, 0x3C, 0xFC, 0xF8, 0xF0, 0xC0, 0x00, 0x00, 0x00, 0x00, 0x00, 0x00, 0x00,
0x00, 0x00, 0x80, 0xE0, 0xF0, 0xFC, 0x7E, 0x3E, 0x1E, 0x06, 0x02, 0x00, 0x00, 0x00, 0x00, 0x00,
0x00, 0x00, 0x00, 0x00, 0x00, 0x00, 0x00, 0x00, 0x00, 0x00, 0x00, 0x00, 0x00, 0x00, 0x00, 0x00,
0x00, 0x00, 0x00, 0x00, 0x00, 0x00, 0x00, 0x00, 0x00, 0x00, 0x00, 0x00, 0x00, 0x00, 0x00, 0x00,
0x00, 0x00, 0x00, 0x00, 0x00, 0x00, 0x00, 0x00, 0x00, 0x00, 0x00, 0x00, 0x00, 0x00, 0x00, 0x00,
0x00, 0x00, 0x00, 0x00, 0x00, 0x00, 0x00, 0xFC, 0xFE, 0xFF, 0x03, 0x01, 0x00, 0xF0, 0xF8, 0x1E,
0x07, 0x01, 0x00, 0x00, 0x00, 0xC0, 0xE0, 0xE0, 0xF0, 0xF0, 0xF8, 0xF8, 0x7C, 0x3C, 0x1F, 0x0F,
0x0F, 0x1F, 0x1B, 0xF8, 0xF0, 0x00, 0x03, 0x0F, 0x8F, 0x8E, 0x00, 0x00, 0x00, 0x00, 0x00, 0x00,
0x00, 0x00, 0x00, 0x00, 0x00, 0x00, 0x00, 0x00, 0x00, 0x00, 0x00, 0x00, 0x00, 0x00, 0x00, 0x00,
0x00, 0x00, 0x00, 0x00, 0x00, 0x00, 0x00, 0x00, 0x00, 0x00, 0x00, 0x00, 0x00, 0x00, 0x00, 0x00,
0x00, 0x00, 0x00, 0x00, 0x00, 0x00, 0x00, 0x00, 0x00, 0x00, 0x00, 0x00, 0x00, 0x00, 0x00, 0x00,
0x00, 0x00, 0x00, 0x00, 0x00, 0x00, 0x00, 0x00, 0x00, 0x00, 0x00, 0x00, 0x00, 0x00, 0x00, 0x00,
0x00, 0x00, 0x00, 0x00, 0x00, 0x00, 0x00, 0x00, 0x00, 0x00, 0x00, 0x00, 0x00, 0x00, 0x00, 0x00,
0x00, 0x00, 0x00, 0x00, 0x00, 0x00, 0x00, 0x00, 0x00, 0x00, 0x00, 0x00, 0x00, 0x00, 0x00, 0x00,
0x00, 0x00, 0x00, 0x00, 0x00, 0x00, 0x00, 0x00, 0x00, 0x00, 0x00, 0x00, 0x00, 0x00, 0x00, 0x00,
0x00, 0x00, 0x1F, 0x7F, 0xFF, 0xFF, 0xE0, 0xC0, 0x80, 0x80, 0x80, 0x80, 0x80, 0xC0, 0xE0, 0xFF,
0xFF, 0x7F, 0x1F, 0x00, 0x00, 0x00, 0x80, 0xC0, 0xF0, 0xF8, 0xFC, 0x7F, 0x1F, 0x0F, 0x03, 0x01,
0x00, 0x00, 0x00, 0x00, 0x00, 0x00, 0x00, 0x00, 0x00, 0x00, 0x00, 0x00, 0x00, 0x00, 0x00, 0x00,
0x00, 0x00, 0x00, 0x00, 0x00, 0x00, 0x00, 0x00, 0x00, 0x00, 0x00, 0x00, 0x00, 0x00, 0x00, 0x00,
0x00, 0x00, 0x00, 0x00, 0x00, 0x00, 0x00, 0x00, 0x00, 0x00, 0x00, 0x00, 0x00, 0x00, 0x00, 0x00,
0x00, 0x00, 0x00, 0x00, 0x00, 0x00, 0x00, 0x00, 0x00, 0x00, 0x00, 0x00, 0x00, 0x00, 0x00, 0x00,
0x00, 0x07, 0x1F, 0x7F, 0xF8, 0xF0, 0xC0, 0x81, 0x07, 0x1E, 0x38, 0x30, 0x00, 0x00, 0x00, 0x00,
0x00, 0x03, 0x03, 0x03, 0x01, 0x00, 0x00, 0x00, 0x00, 0x00, 0x30, 0x38, 0x1E, 0x87, 0xE1, 0xF8,
0x3E, 0x1F, 0xCF, 0xFF, 0xFF, 0xFE, 0xF8, 0xE0, 0xC0, 0x00, 0x00, 0x00, 0x00, 0x00, 0x00, 0x00,
0x00, 0x00, 0x00, 0x00, 0x00, 0x00, 0x00, 0x00, 0x00, 0x00, 0x00, 0x00, 0x00, 0x00, 0x00, 0x00,
0x00, 0x00, 0x00, 0x00, 0x00, 0x00, 0x00, 0x00, 0x00, 0x00, 0x00, 0x00, 0x00, 0x00, 0x00, 0x00,
0x00, 0x00, 0x00, 0x00, 0x00, 0x00, 0x00, 0x00, 0x00, 0x00, 0x00, 0x00, 0x00, 0x00, 0x00, 0x00,
0x00, 0x00, 0x00, 0x00, 0x00, 0x00, 0x00, 0x00, 0x00, 0x00, 0x00, 0x00, 0x00, 0x00, 0x00, 0x00,
0x00, 0x00, 0x00, 0x00, 0x00, 0x00, 0x00, 0x00, 0x00, 0x00, 0x00, 0x00, 0x00, 0x00, 0x00, 0x00,
0x00, 0x00, 0x00, 0x00, 0x00, 0x00, 0x00, 0x00, 0x00, 0x00, 0x00, 0x00, 0x00, 0x00, 0x00, 0x00,
0x00, 0x00, 0x00, 0x00, 0x00, 0x00, 0x00, 0x00, 0x00, 0x00, 0x00, 0x00, 0x00, 0x00, 0x00, 0x01,
0x01, 0x03, 0x03, 0x03, 0x03, 0x03, 0x03, 0x03, 0x01, 0x01, 0x00, 0x80, 0xE0, 0xF0, 0xFC, 0xFE,
0x3F, 0x1F, 0x07, 0x03, 0x00, 0x00, 0xE0, 0xF8, 0xFC, 0xFE, 0x1E, 0x0F, 0x07, 0x07, 0x07, 0x07,
0x07, 0x0F, 0x1E, 0xFE, 0xFC, 0xF8, 0xE0, 0x00, 0x00, 0x00, 0x00, 0x00, 0x00, 0x00, 0x00, 0x00,
0x00, 0x00, 0x00, 0x00, 0x00, 0x00, 0x00, 0x00, 0x00, 0x00, 0x00, 0x00, 0x00, 0x00, 0x00, 0x00,
0x00, 0x00, 0x00, 0x00, 0x00, 0x00, 0x00, 0x00, 0x00, 0x00, 0x00, 0x00, 0x00, 0x00, 0x00, 0x00,
0x00, 0x00, 0x00, 0x00, 0x00, 0x00, 0x00, 0x00, 0x00, 0x00, 0x00, 0x00, 0x00, 0x00, 0x00, 0x01,
0x03, 0x07, 0x07, 0x0E, 0x1C, 0x1C, 0x1C, 0x38, 0x78, 0x78, 0x70, 0x70, 0x70, 0x70, 0x70, 0x70,
0x70, 0x70, 0x70, 0x00, 0x00, 0xFC, 0xFE, 0xCF, 0x03, 0x00, 0x78, 0xFF, 0xFF, 0xFF, 0xFF, 0xFF,
0xFF, 0xFF, 0xFF, 0xFF, 0xFC, 0x00, 0x00, 0x00, 0x00, 0x00, 0x00, 0x00, 0x00, 0x00, 0x00, 0x00,
0x00, 0x00, 0x00, 0x00, 0x00, 0x00, 0x00, 0x00, 0x00, 0x00, 0x00, 0x00, 0x00, 0x00, 0x00, 0x00,
0x00, 0x00, 0x00, 0x00, 0x00, 0x00, 0x00, 0x00, 0x00, 0x00, 0x00, 0x00, 0x00, 0x00, 0x00, 0x00,
0x00, 0x00, 0x00, 0x00, 0x00, 0x00, 0x00, 0x00, 0x00, 0x00, 0x00, 0x00, 0x00, 0x00, 0x00, 0x00,
0x00, 0x00, 0x00, 0x00, 0x00, 0x00, 0x00, 0x00, 0x00, 0x00, 0x00, 0x00, 0x00, 0x00, 0x00, 0x00,
0x00, 0x00, 0x00, 0x00, 0x00, 0x00, 0x00, 0x00, 0x00, 0x00, 0x00, 0x00, 0x00, 0x00, 0x00, 0x00,
0x00, 0x00, 0x00, 0x00, 0x00, 0x00, 0x00, 0x00, 0x00, 0x00, 0x00, 0x00, 0x00, 0x00, 0x00, 0x00,
0x00, 0x00, 0x00, 0x00, 0x00, 0x00, 0x00, 0x00, 0x00, 0x00, 0x00, 0x00, 0x00, 0x00, 0x00, 0x00,
0xC0, 0xE0, 0xF8, 0xFC, 0x7F, 0x1F, 0x0F, 0x07, 0x01, 0x00, 0x00, 0x00, 0x00, 0x00, 0x00, 0x00,
0x0F, 0x3F, 0x7F, 0xFF, 0xF0, 0xE0, 0xC0, 0xC0, 0xC0, 0xC0, 0xC0, 0xE0, 0xF0, 0xFF, 0x7F, 0x3F,
0x0F, 0x00, 0x00, 0x00, 0x00, 0x00, 0x00, 0x00, 0x00, 0x00, 0x00, 0x00, 0x00, 0x00, 0x00, 0x00,
0x00, 0x00, 0x00, 0x00, 0x00, 0x00, 0x00, 0x00, 0x00, 0x00, 0x00, 0x00, 0x00, 0x00, 0x00, 0x00,
0x00, 0x00, 0x00, 0x00, 0x00, 0x00, 0x00, 0x00, 0x00, 0x00, 0x00, 0x00, 0x00, 0x00, 0x00, 0x00,
0x00, 0x00, 0x00, 0x00, 0x00, 0x00, 0x00, 0x00, 0x00, 0x00, 0x00, 0x00, 0x00, 0x00, 0x00, 0x00,
0x00, 0x00, 0x00, 0x00, 0x00, 0x00, 0x00, 0x00, 0x00, 0x00, 0x00, 0x00, 0x00, 0x00, 0x00, 0x00,
0x01, 0x03, 0x07, 0x0E, 0x1C, 0x1F, 0x1F, 0x1F, 0x1F, 0x1F, 0x0F, 0x07, 0x03, 0x01, 0x00, 0x00,
0x00, 0x00, 0x00, 0x00, 0x00, 0x00, 0x00, 0x00, 0x00, 0x00, 0x00, 0x00, 0x00, 0x00, 0x00, 0x00,
0x00, 0x00, 0x00, 0x00, 0x00, 0x00, 0x00, 0x00, 0x00, 0x00, 0x00, 0x00, 0x00, 0x00, 0x00, 0x00,
0x00, 0x00, 0x00, 0x00, 0x00, 0x00, 0x00, 0x00, 0x00, 0x00, 0x00, 0x00, 0x00, 0x00, 0x00, 0x00,
0x00, 0x00, 0x00, 0x00, 0x00, 0x00, 0x00, 0x00, 0x00, 0x00, 0x00, 0x00, 0x00, 0x00, 0x00, 0x00,
0x00, 0x00, 0x00, 0x00, 0x00, 0x00, 0x00, 0x00, 0x00, 0x00, 0x00, 0x00, 0x00, 0x00, 0x00, 0x00,
0x00, 0x00, 0x00, 0x00, 0x00, 0x00, 0x00, 0x00, 0x00, 0x00, 0x00, 0x00, 0x00, 0x00, 0x00, 0x00,
0x00, 0x00, 0x00, 0x00, 0x00, 0x00, 0x00, 0x00, 0x00, 0x00, 0x00, 0x00, 0x00, 0x00, 0x00, 0x00,
0x00, 0x00, 0x00, 0x00, 0x00, 0x00, 0x00, 0x00, 0x00, 0x01, 0x01, 0x01, 0x01, 0x00, 0x00, 0x00,
0x00, 0x00, 0x00, 0x00, 0x00, 0x00, 0x00, 0x00, 0x00, 0x00, 0x00, 0x00, 0x00, 0x00, 0x00, 0x01,
0x01, 0x01, 0x01, 0x01, 0x01, 0x01, 0x00, 0x00, 0x00, 0x00, 0x00, 0x00, 0x00, 0x00, 0x00, 0x00,
0x00, 0x00, 0x00, 0x00, 0x00, 0x00, 0x00, 0x00, 0x00, 0x00, 0x00, 0x00, 0x00, 0x00, 0x00, 0x00,
0x00, 0x00, 0x00, 0x00, 0x00, 0x00, 0x00, 0x00, 0x00, 0x00, 0x00, 0x00, 0x00, 0x00, 0x00, 0x00
};

//------------------------------------------------------------------------------
// File generated by LCD Assistant
// http://en.radzio.dxp.pl/bitmap_converter/
//------------------------------------------------------------------------------

void DrawScr(const unsigned char* lut){ // Update screen
		EPD_init(lut);
		if(lut==lut_full_update){EPD_Display(image);}else{EPD_DisplayPart(image);}
		EPD_update();
		EPD_sleep();

}
//####################################################################//

void Deinit(){ // DeInit Prriph
	HAL_I2C_DeInit(&hi2c1);
	HAL_ADC_DeInit(&hadc);

}
//####################################################################//

void Sleep (void){

HAL_PWR_EnterSTOPMode(PWR_LOWPOWERREGULATOR_ON, PWR_SLEEPENTRY_WFI); // enter sleep mode

}
//####################################################################//

int8_t user_i2c_read(uint8_t id, uint8_t reg_addr, uint8_t *data, uint16_t len){ // bme280 read fnc
  if(HAL_I2C_Master_Transmit(&hi2c1, (id << 1), &reg_addr, 1, 10) != HAL_OK) return -1;
  if(HAL_I2C_Master_Receive(&hi2c1, (id << 1) | 0x01, data, len, 10) != HAL_OK) return -1;
  return 0;
}
//####################################################################//
void user_delay_ms(uint32_t period){ // bme280 delay fnc
  HAL_Delay(period);
}
//####################################################################//
int8_t user_i2c_write(uint8_t id, uint8_t reg_addr, uint8_t *data, uint16_t len){ // bme280 write fnc
  int8_t *buf;
  buf = malloc(len +1);
  buf[0] = reg_addr;
  memcpy(buf +1, data, len);

  if(HAL_I2C_Master_Transmit(&hi2c1, (id << 1), (uint8_t*)buf, len + 1, HAL_MAX_DELAY) != HAL_OK) return -1;

  free(buf);
  return 0;
}

//####################################################################//
uint16_t ConfigRead_ADC(uint32_t channel){ // Read ADC
	uint16_t ret;

	ADC_ChannelConfTypeDef sConfig = {0};
  sConfig.Channel = channel; // set callibration channel
  sConfig.Rank = 1;
  HAL_ADC_ConfigChannel(&hadc, &sConfig);
	HAL_Delay(3);
  HAL_ADC_Start(&hadc);
	HAL_ADC_PollForConversion(&hadc, 1000);
	ret=HAL_ADC_GetValue(&hadc);
	HAL_ADC_Stop(&hadc);
	return ret;
}
//####################################################################//
void Draw (void){
#define X 70
Paint_Clear(0xff);
Paint_Image(0,4,(uint8_t *)MainScr, BLACK);
memset(Str,0,sizeof(Str));
sprintf(Str, "%+7.2f", temperature);
Paint_String(X, 10, Str, &Font24, BLACK, LEFT);
memset(Str,0,sizeof(Str));
sprintf(Str, "%7.1f", pressure);
Paint_String(X, 50, Str, &Font24, BLACK, LEFT);
memset(Str,0,sizeof(Str));
sprintf(Str, "%7.2f", humidity);
Paint_String(X, 95, Str, &Font24, BLACK, LEFT);

	if(Battery*1000>3325){
	Paint_Image(218,9,(uint8_t *)Batt_Full, BLACK);
	}
	if(Battery*1000<3325&&Battery*1000>3050){
	Paint_Image(218,9,(uint8_t *)Batt_75, BLACK);
	}

		if(Battery*1000<3050&&Battery*1000>2775){
	Paint_Image(218,9,(uint8_t *)Batt_50, BLACK);
	}
	if(Battery*1000<2775&&Battery*1000>2550){
	Paint_Image(218,9,(uint8_t *)Batt_25, BLACK);
	}
	if(Battery*1000<2500){
	Paint_Image(218,9,(uint8_t *)Batt_0, BLACK);
	}

DrawScr(lut_partial_update);

}
//#########$$$$$$$$$$$$$$###########################
void Battery_Measured(void){ // Voltage Calculate
	uint16_t REF_ADC;

REF_ADC=ConfigRead_ADC(ADC_CHANNEL_VREFINT);
Battery =((4096*1.224)/REF_ADC)*1.035; // 1.224V - VrefInt; 1.035 - Callibrate koefficient

}
//#########$$$$$$$$$$$$$$###########################
void HAL_RTCEx_WakeUpTimerEventCallback(RTC_HandleTypeDef *hrtc){
  /* Prevent unused argument(s) compilation warning */
UNUSED(hrtc);
	RTC_TimeTypeDef sTime = {0};
  RTC_DateTypeDef sDate = {0};

	HAL_RTC_GetTime(hrtc, &sTime,RTC_FORMAT_BIN);
	HAL_RTC_GetDate(hrtc, &sDate,RTC_FORMAT_BIN);
RT_C.seconds = sTime.Seconds;
RT_C.mins = sTime.Minutes;
RT_C.hours = sTime.Hours;
RT_C.day = sDate.Date;
RT_C.month = sDate.Month;
RT_C.year = sDate.Year;
RT_C.weekday = sDate.WeekDay;

  /* NOTE : This function Should not be modified, when the callback is needed,
            the HAL_RTCEx_WakeUpTimerEventCallback could be implemented in the user file
   */
}
//####################################################################//

/* USER CODE END 0 */

int main(void)
{

  /* MCU Configuration--------------------------------------------------------*/

  /* Reset of all peripherals, Initializes the Flash interface and the Systick. */
  HAL_Init();

  /* Configure the system clock */
  SystemClock_Config();

  /* Initialize all configured peripherals */
  MX_GPIO_Init();
  MX_I2C1_Init();
  MX_SPI2_Init();
  MX_ADC_Init();
  MX_RTC_Init();
  /* USER CODE BEGIN 2 */
 /* BME280 Config */
  dev.dev_id = BME280_I2C_ADDR_PRIM;
  dev.intf = BME280_I2C_INTF;
  dev.read = user_i2c_read;
  dev.write = user_i2c_write;
  dev.delay_ms = user_delay_ms;

  rslt = bme280_init(&dev);

  dev.settings.osr_h = BME280_OVERSAMPLING_1X;
  dev.settings.osr_p = BME280_OVERSAMPLING_16X;
  dev.settings.osr_t = BME280_OVERSAMPLING_2X;
  dev.settings.filter = BME280_FILTER_COEFF_16;
  rslt = bme280_set_sensor_settings(BME280_OSR_PRESS_SEL | BME280_OSR_TEMP_SEL | BME280_OSR_HUM_SEL | BME280_FILTER_SEL, &dev);
/* BME280 Config */

/* Display init */
		EPD_init(lut_full_update);
		EPD_clear(0xff);
		EPD_update();
		EPD_sleep();
/* Display init */
Battery_Measured();
  /* USER CODE END 2 */

  /* Infinite loop */
  while (1)
  {

    /* USER CODE BEGIN 3 */

		if(RT_C.mins!=Old_min){
					MX_I2C1_Init();
					MX_ADC_Init();

		rslt = bme280_set_sensor_mode(BME280_FORCED_MODE, &dev);
    dev.delay_ms(40);
    rslt = bme280_get_sensor_data(BME280_ALL, &comp_data, &dev);
    if(rslt == BME280_OK)
    {
      temperature = comp_data.temperature / 100.0;      /* °C  */
      humidity = comp_data.humidity / 1024.0;           /* %   */
      pressure = comp_data.pressure / 10000.0;          /* hPa */

    }
		rslt = bme280_set_sensor_mode(BME280_SLEEP_MODE, &dev); //

		HAL_I2C_DeInit(&hi2c1);
		Battery_Measured();
		Draw();

		Old_min=RT_C.mins;
		Deinit();
		}
		Sleep ();
  }
  /* USER CODE END 3 */
}

void SystemClock_Config(void)
{
  RCC_OscInitTypeDef RCC_OscInitStruct = {0};
  RCC_ClkInitTypeDef RCC_ClkInitStruct = {0};
  RCC_PeriphCLKInitTypeDef PeriphClkInit = {0};

  /** Configure the main internal regulator output voltage
  */
  __HAL_PWR_VOLTAGESCALING_CONFIG(PWR_REGULATOR_VOLTAGE_SCALE1);
  /** Initializes the RCC Oscillators according to the specified parameters
  * in the RCC_OscInitTypeDef structure.
  */
  RCC_OscInitStruct.OscillatorType = RCC_OSCILLATORTYPE_LSI|RCC_OSCILLATORTYPE_MSI;
  RCC_OscInitStruct.LSIState = RCC_LSI_ON;
  RCC_OscInitStruct.MSIState = RCC_MSI_ON;
  RCC_OscInitStruct.MSICalibrationValue = 0;
  RCC_OscInitStruct.MSIClockRange = RCC_MSIRANGE_6;
  RCC_OscInitStruct.PLL.PLLState = RCC_PLL_NONE;
  if (HAL_RCC_OscConfig(&RCC_OscInitStruct) != HAL_OK)
  {
    Error_Handler();
  }
  /** Initializes the CPU, AHB and APB buses clocks
  */
  RCC_ClkInitStruct.ClockType = RCC_CLOCKTYPE_HCLK|RCC_CLOCKTYPE_SYSCLK
                              |RCC_CLOCKTYPE_PCLK1|RCC_CLOCKTYPE_PCLK2;
  RCC_ClkInitStruct.SYSCLKSource = RCC_SYSCLKSOURCE_MSI;
  RCC_ClkInitStruct.AHBCLKDivider = RCC_SYSCLK_DIV1;
  RCC_ClkInitStruct.APB1CLKDivider = RCC_HCLK_DIV1;
  RCC_ClkInitStruct.APB2CLKDivider = RCC_HCLK_DIV1;

  if (HAL_RCC_ClockConfig(&RCC_ClkInitStruct, FLASH_LATENCY_0) != HAL_OK)
  {
    Error_Handler();
  }
  PeriphClkInit.PeriphClockSelection = RCC_PERIPHCLK_I2C1|RCC_PERIPHCLK_RTC;
  PeriphClkInit.I2c1ClockSelection = RCC_I2C1CLKSOURCE_PCLK1;
  PeriphClkInit.RTCClockSelection = RCC_RTCCLKSOURCE_LSI;
  if (HAL_RCCEx_PeriphCLKConfig(&PeriphClkInit) != HAL_OK)
  {
    Error_Handler();
  }
}

static void MX_ADC_Init(void)
{

  ADC_ChannelConfTypeDef sConfig = {0};

  /** Configure the global features of the ADC (Clock, Resolution, Data Alignment and number of conversion)
  */
  hadc.Instance = ADC1;
  hadc.Init.OversamplingMode = DISABLE;
  hadc.Init.ClockPrescaler = ADC_CLOCK_SYNC_PCLK_DIV1;
  hadc.Init.Resolution = ADC_RESOLUTION_12B;
  hadc.Init.SamplingTime = ADC_SAMPLETIME_160CYCLES_5;
  hadc.Init.ScanConvMode = ADC_SCAN_DIRECTION_FORWARD;
  hadc.Init.DataAlign = ADC_DATAALIGN_RIGHT;
  hadc.Init.ContinuousConvMode = DISABLE;
  hadc.Init.DiscontinuousConvMode = DISABLE;
  hadc.Init.ExternalTrigConvEdge = ADC_EXTERNALTRIGCONVEDGE_NONE;
  hadc.Init.ExternalTrigConv = ADC_SOFTWARE_START;
  hadc.Init.DMAContinuousRequests = DISABLE;
  hadc.Init.EOCSelection = ADC_EOC_SINGLE_CONV;
  hadc.Init.Overrun = ADC_OVR_DATA_PRESERVED;
  hadc.Init.LowPowerAutoWait = DISABLE;
  hadc.Init.LowPowerFrequencyMode = DISABLE;
  hadc.Init.LowPowerAutoPowerOff = DISABLE;
  if (HAL_ADC_Init(&hadc) != HAL_OK)
  {
    Error_Handler();
  }
  /** Configure for the selected ADC regular channel to be converted.
  */
  sConfig.Channel = ADC_CHANNEL_VREFINT;
  sConfig.Rank = ADC_RANK_CHANNEL_NUMBER;
  if (HAL_ADC_ConfigChannel(&hadc, &sConfig) != HAL_OK)
  {
    Error_Handler();
  }

}

static void MX_I2C1_Init(void)
{

  hi2c1.Instance = I2C1;
  hi2c1.Init.Timing = 0x00100E16;
  hi2c1.Init.OwnAddress1 = 0;
  hi2c1.Init.AddressingMode = I2C_ADDRESSINGMODE_7BIT;
  hi2c1.Init.DualAddressMode = I2C_DUALADDRESS_DISABLE;
  hi2c1.Init.OwnAddress2 = 0;
  hi2c1.Init.OwnAddress2Masks = I2C_OA2_NOMASK;
  hi2c1.Init.GeneralCallMode = I2C_GENERALCALL_DISABLE;
  hi2c1.Init.NoStretchMode = I2C_NOSTRETCH_DISABLE;
  if (HAL_I2C_Init(&hi2c1) != HAL_OK)
  {
    Error_Handler();
  }
  /** Configure Analogue filter
  */
  if (HAL_I2CEx_ConfigAnalogFilter(&hi2c1, I2C_ANALOGFILTER_DISABLE) != HAL_OK)
  {
    Error_Handler();
  }
  /** Configure Digital filter
  */
  if (HAL_I2CEx_ConfigDigitalFilter(&hi2c1, 0) != HAL_OK)
  {
    Error_Handler();
  }

}

static void MX_RTC_Init(void)
{

  RTC_TimeTypeDef sTime = {0};
  RTC_DateTypeDef sDate = {0};

  /** Initialize RTC Only
  */
  hrtc.Instance = RTC;
  hrtc.Init.HourFormat = RTC_HOURFORMAT_24;
  hrtc.Init.AsynchPrediv = 99;
  hrtc.Init.SynchPrediv = 369;
  hrtc.Init.OutPut = RTC_OUTPUT_DISABLE;
  hrtc.Init.OutPutRemap = RTC_OUTPUT_REMAP_NONE;
  hrtc.Init.OutPutPolarity = RTC_OUTPUT_POLARITY_HIGH;
  hrtc.Init.OutPutType = RTC_OUTPUT_TYPE_OPENDRAIN;
  if (HAL_RTC_Init(&hrtc) != HAL_OK)
  {
    Error_Handler();
  }

  /** Initialize RTC and set the Time and Date
  */
  sTime.Hours = 0x0;
  sTime.Minutes = 0x0;
  sTime.Seconds = 0x0;
  sTime.DayLightSaving = RTC_DAYLIGHTSAVING_NONE;
  sTime.StoreOperation = RTC_STOREOPERATION_RESET;
  if (HAL_RTC_SetTime(&hrtc, &sTime, RTC_FORMAT_BCD) != HAL_OK)
  {
    Error_Handler();
  }
  sDate.WeekDay = RTC_WEEKDAY_MONDAY;
  sDate.Month = RTC_MONTH_JANUARY;
  sDate.Date = 0x1;
  sDate.Year = 0x0;

  if (HAL_RTC_SetDate(&hrtc, &sDate, RTC_FORMAT_BCD) != HAL_OK)
  {
    Error_Handler();
  }
  /** Enable the WakeUp
  */
  if (HAL_RTCEx_SetWakeUpTimer_IT(&hrtc, 23124, RTC_WAKEUPCLOCK_RTCCLK_DIV8) != HAL_OK)
  {
    Error_Handler();
  }

}

static void MX_SPI2_Init(void)
{

  /* SPI2 parameter configuration*/
  hspi2.Instance = SPI2;
  hspi2.Init.Mode = SPI_MODE_MASTER;
  hspi2.Init.Direction = SPI_DIRECTION_1LINE;
  hspi2.Init.DataSize = SPI_DATASIZE_8BIT;
  hspi2.Init.CLKPolarity = SPI_POLARITY_LOW;
  hspi2.Init.CLKPhase = SPI_PHASE_1EDGE;
  hspi2.Init.NSS = SPI_NSS_SOFT;
  hspi2.Init.BaudRatePrescaler = SPI_BAUDRATEPRESCALER_2;
  hspi2.Init.FirstBit = SPI_FIRSTBIT_MSB;
  hspi2.Init.TIMode = SPI_TIMODE_DISABLE;
  hspi2.Init.CRCCalculation = SPI_CRCCALCULATION_DISABLE;
  hspi2.Init.CRCPolynomial = 7;
  if (HAL_SPI_Init(&hspi2) != HAL_OK)
  {
    Error_Handler();
  }

}

static void MX_GPIO_Init(void)
{
  GPIO_InitTypeDef GPIO_InitStruct = {0};

  /* GPIO Ports Clock Enable */
  __HAL_RCC_GPIOC_CLK_ENABLE();
  __HAL_RCC_GPIOH_CLK_ENABLE();
  __HAL_RCC_GPIOA_CLK_ENABLE();
  __HAL_RCC_GPIOB_CLK_ENABLE();

  /*Configure GPIO pin Output Level */
  HAL_GPIO_WritePin(GPIOB, RST_EPD_Pin|CS_EPD_Pin, GPIO_PIN_SET);

  /*Configure GPIO pin Output Level */
  HAL_GPIO_WritePin(DC_EPD_GPIO_Port, DC_EPD_Pin, GPIO_PIN_RESET);

  /*Configure GPIO pins : PC13 PC14 PC15 */
  GPIO_InitStruct.Pin = GPIO_PIN_13|GPIO_PIN_14|GPIO_PIN_15;
  GPIO_InitStruct.Mode = GPIO_MODE_ANALOG;
  GPIO_InitStruct.Pull = GPIO_NOPULL;
  HAL_GPIO_Init(GPIOC, &GPIO_InitStruct);

  /*Configure GPIO pins : PH0 PH1 */
  GPIO_InitStruct.Pin = GPIO_PIN_0|GPIO_PIN_1;
  GPIO_InitStruct.Mode = GPIO_MODE_ANALOG;
  GPIO_InitStruct.Pull = GPIO_NOPULL;
  HAL_GPIO_Init(GPIOH, &GPIO_InitStruct);

  /*Configure GPIO pins : PA0 PA1 PA2 PA3
                           PA4 PA5 PA6 PA7
                           PA8 PA9 PA10 PA11
                           PA12 PA13 PA14 PA15 */
  GPIO_InitStruct.Pin = GPIO_PIN_0|GPIO_PIN_1|GPIO_PIN_2|GPIO_PIN_3
                          |GPIO_PIN_4|GPIO_PIN_5|GPIO_PIN_6|GPIO_PIN_7
                          |GPIO_PIN_8|GPIO_PIN_9|GPIO_PIN_10|GPIO_PIN_11
                          |GPIO_PIN_12|GPIO_PIN_13|GPIO_PIN_14|GPIO_PIN_15;
  GPIO_InitStruct.Mode = GPIO_MODE_ANALOG;
  GPIO_InitStruct.Pull = GPIO_NOPULL;
  HAL_GPIO_Init(GPIOA, &GPIO_InitStruct);

  /*Configure GPIO pins : PB0 PB1 PB14 PB3
                           PB4 PB5 PB8 PB9 */
  GPIO_InitStruct.Pin = GPIO_PIN_0|GPIO_PIN_1|GPIO_PIN_14|GPIO_PIN_3
                          |GPIO_PIN_4|GPIO_PIN_5|GPIO_PIN_8|GPIO_PIN_9;
  GPIO_InitStruct.Mode = GPIO_MODE_ANALOG;
  GPIO_InitStruct.Pull = GPIO_NOPULL;
  HAL_GPIO_Init(GPIOB, &GPIO_InitStruct);

  /*Configure GPIO pin : BUSY_EPD_Pin */
  GPIO_InitStruct.Pin = BUSY_EPD_Pin;
  GPIO_InitStruct.Mode = GPIO_MODE_INPUT;
  GPIO_InitStruct.Pull = GPIO_NOPULL;
  HAL_GPIO_Init(BUSY_EPD_GPIO_Port, &GPIO_InitStruct);

  /*Configure GPIO pin : RST_EPD_Pin */
  GPIO_InitStruct.Pin = RST_EPD_Pin;
  GPIO_InitStruct.Mode = GPIO_MODE_OUTPUT_PP;
  GPIO_InitStruct.Pull = GPIO_PULLUP;
  GPIO_InitStruct.Speed = GPIO_SPEED_FREQ_LOW;
  HAL_GPIO_Init(RST_EPD_GPIO_Port, &GPIO_InitStruct);

  /*Configure GPIO pins : DC_EPD_Pin CS_EPD_Pin */
  GPIO_InitStruct.Pin = DC_EPD_Pin|CS_EPD_Pin;
  GPIO_InitStruct.Mode = GPIO_MODE_OUTPUT_PP;
  GPIO_InitStruct.Pull = GPIO_NOPULL;
  GPIO_InitStruct.Speed = GPIO_SPEED_FREQ_LOW;
  HAL_GPIO_Init(GPIOB, &GPIO_InitStruct);

}

void Error_Handler(void)
{
  __disable_irq();
  while (1)
  {
  }
}

/************************ (C) COPYRIGHT STMicroelectronics *****END OF FILE****/
